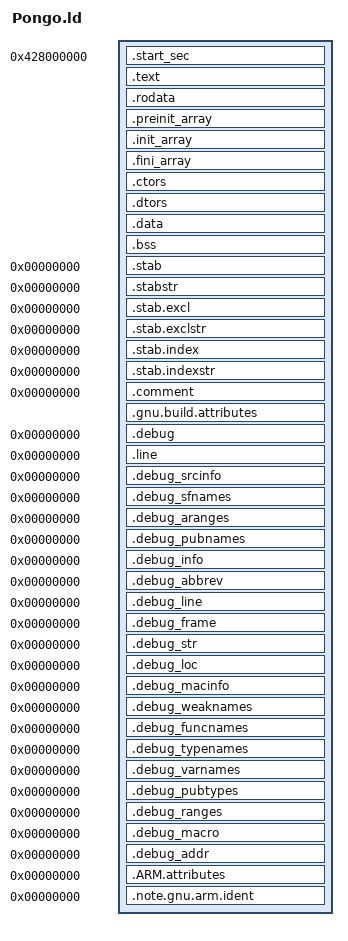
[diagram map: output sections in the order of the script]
/* pongoOS linker script 
 * Parts Copyright (C) 2019 checkra1n team
 * Parts Copyright (C) 2014-2019 Free Software Foundation, Inc.
 * Copying and distribution of this script, with or without modification,
 * are permitted in any medium without royalty provided the copyright
 * notice and this notice are preserved. 
 */

OUTPUT_FORMAT("elf64-littleaarch64")
OUTPUT_ARCH(aarch64)

ENTRY_INIT_STACK_SIZE = 0x2000;

SECTIONS
{
  /* the entry point, before enabling paging. The code to enable paing
   needs to have the same virtual/physical address. entry.S and start.c
   run in this initial setting.*/
  /* . = 0x10000; */
  . = 0x428000000;
  
  .start_sec : {
    build/entry.o(.text)

    build/entry.o(.rodata .rodata.*)

    build/entry.o(.data .data.*)

    build/entry.o(.bss .bss.* COMMON)
  }

  .text : { /** here to make code also copied into phymem **/
    *(EXCLUDE_FILE(*/crt0.o).text .text.* .gnu.linkonce.t.*)
  }


  .rodata : {
    *(.rodata .rodata.* .gnu.linkonce.r.*)
  }

    .preinit_array    :
  {
    PROVIDE_HIDDEN (__preinit_array_start = .);
    KEEP (*(.preinit_array))
    PROVIDE_HIDDEN (__preinit_array_end = .);
  }
  .init_array    :
  {
    PROVIDE_HIDDEN (__init_array_start = .);
    KEEP (*(SORT_BY_INIT_PRIORITY(.init_array.*) SORT_BY_INIT_PRIORITY(.ctors.*)))
    KEEP (*(.init_array EXCLUDE_FILE (*crtbegin.o *crtbegin?.o *crtend.o *crtend?.o ) .ctors))
    PROVIDE_HIDDEN (__init_array_end = .);
  }
  .fini_array    :
  {
    PROVIDE_HIDDEN (__fini_array_start = . + 0x400000000);
    KEEP (*(SORT_BY_INIT_PRIORITY(.fini_array.*) SORT_BY_INIT_PRIORITY(.dtors.*)))
    KEEP (*(.fini_array EXCLUDE_FILE (*crtbegin.o *crtbegin?.o *crtend.o *crtend?.o ) .dtors))
    PROVIDE_HIDDEN (__fini_array_end = . + 0x400000000);
  }
  .ctors          :
  {
    /* gcc uses crtbegin.o to find the start of
       the constructors, so we make sure it is
       first.  Because this is a wildcard, it
       doesn't matter if the user does not
       actually link against crtbegin.o; the
       linker won't look for a file to match a
       wildcard.  The wildcard also means that it
       doesn't matter which directory crtbegin.o
       is in.  */
    KEEP (*crtbegin.o(.ctors))
    KEEP (*crtbegin?.o(.ctors))
    /* We don't want to include the .ctor section from
       the crtend.o file until after the sorted ctors.
       The .ctor section from the crtend file contains the
       end of ctors marker and it must be last */
    KEEP (*(EXCLUDE_FILE (*crtend.o *crtend?.o ) .ctors))
    KEEP (*(SORT(.ctors.*)))
    KEEP (*(.ctors))
  }
  .dtors          :
  {
    KEEP (*crtbegin.o(.dtors))
    KEEP (*crtbegin?.o(.dtors))
    KEEP (*(EXCLUDE_FILE (*crtend.o *crtend?.o ) .dtors))
    KEEP (*(SORT(.dtors.*)))
    KEEP (*(.dtors))
  }

  /* aligned the data to a (4K) page, so it can be assigned
   different protection than the code*/
  . = ALIGN(0x1000);

  PROVIDE (data_start = .);

  .data : {
    *(.data .data.*)
  }

  __bss_start = .;
  .bss : {
    *(.bss .bss.* COMMON)
    . = ALIGN(. != 0 ? 64 / 8 : 1);
  }
  __bss_end = .;
  . = ALIGN(0x1000);
  PROVIDE (end = .);
  . = ALIGN(32 / 8);


    /* Stabs debugging sections.  */
  .stab          0 : { *(.stab) }
  .stabstr       0 : { *(.stabstr) }
  .stab.excl     0 : { *(.stab.excl) }
  .stab.exclstr  0 : { *(.stab.exclstr) }
  .stab.index    0 : { *(.stab.index) }
  .stab.indexstr 0 : { *(.stab.indexstr) }
  .comment       0 : { *(.comment) }
  .gnu.build.attributes : { *(.gnu.build.attributes .gnu.build.attributes.*) }
  /* DWARF debug sections.
     Symbols in the DWARF debugging sections are relative to the beginning
     of the section so we begin them at 0.  */
  /* DWARF 1 */
  .debug          0 : { *(.debug) }
  .line           0 : { *(.line) }
  /* GNU DWARF 1 extensions */
  .debug_srcinfo  0 : { *(.debug_srcinfo) }
  .debug_sfnames  0 : { *(.debug_sfnames) }
  /* DWARF 1.1 and DWARF 2 */
  .debug_aranges  0 : { *(.debug_aranges) }
  .debug_pubnames 0 : { *(.debug_pubnames) }
  /* DWARF 2 */
  .debug_info     0 : { *(.debug_info .gnu.linkonce.wi.*) }
  .debug_abbrev   0 : { *(.debug_abbrev) }
  .debug_line     0 : { *(.debug_line .debug_line.* .debug_line_end) }
  .debug_frame    0 : { *(.debug_frame) }
  .debug_str      0 : { *(.debug_str) }
  .debug_loc      0 : { *(.debug_loc) }
  .debug_macinfo  0 : { *(.debug_macinfo) }
  /* SGI/MIPS DWARF 2 extensions */
  .debug_weaknames 0 : { *(.debug_weaknames) }
  .debug_funcnames 0 : { *(.debug_funcnames) }
  .debug_typenames 0 : { *(.debug_typenames) }
  .debug_varnames  0 : { *(.debug_varnames) }
  /* DWARF 3 */
  .debug_pubtypes 0 : { *(.debug_pubtypes) }
  .debug_ranges   0 : { *(.debug_ranges) }
  /* DWARF Extension.  */
  .debug_macro    0 : { *(.debug_macro) }
  .debug_addr     0 : { *(.debug_addr) }
  .ARM.attributes 0 : { KEEP (*(.ARM.attributes)) KEEP (*(.gnu.attributes)) }
  .note.gnu.arm.ident 0 : { KEEP (*(.note.gnu.arm.ident)) }
  /DISCARD/ : { *(.note.GNU-stack) *(.gnu_debuglink) *(.gnu.lto_*) }

}

